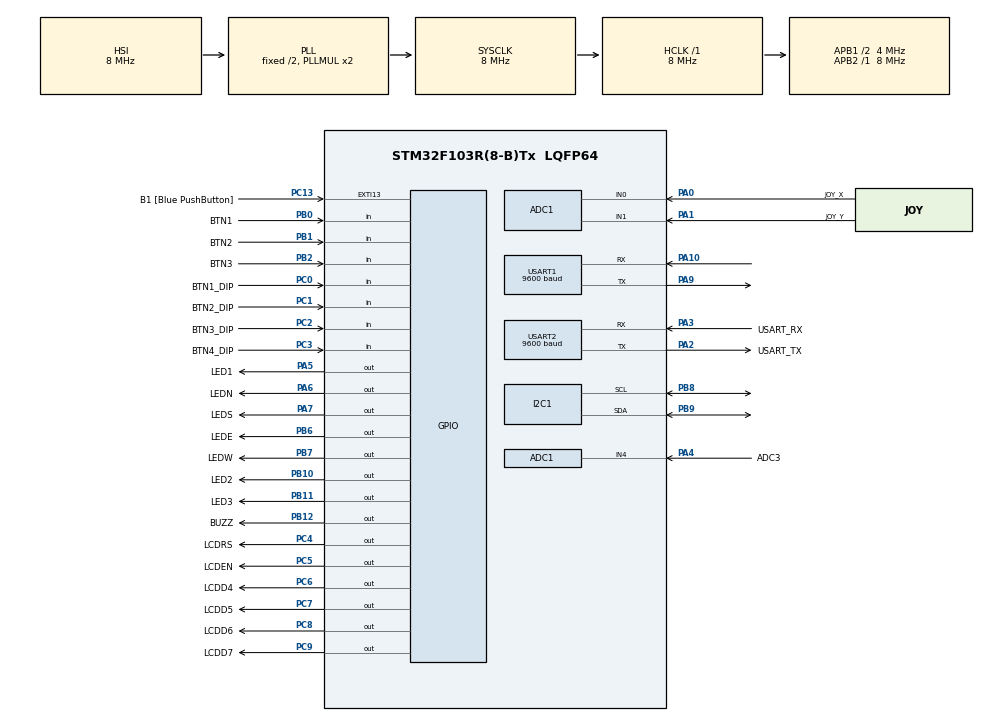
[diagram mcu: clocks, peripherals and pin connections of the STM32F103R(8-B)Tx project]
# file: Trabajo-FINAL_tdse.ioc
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ADC1.Channel-3\#ChannelRegularConversion=ADC_CHANNEL_0
ADC1.Channel-4\#ChannelRegularConversion=ADC_CHANNEL_1
ADC1.Channel-5\#ChannelRegularConversion=ADC_CHANNEL_4
ADC1.ContinuousConvMode=ENABLE
ADC1.DataAlign=ADC_DATAALIGN_RIGHT
ADC1.NbrOfConversion=3
ADC1.NbrOfConversionFlag=1
ADC1.Rank-3\#ChannelRegularConversion=1
ADC1.Rank-4\#ChannelRegularConversion=2
ADC1.Rank-5\#ChannelRegularConversion=3
ADC1.SamplingTime-3\#ChannelRegularConversion=ADC_SAMPLETIME_71CYCLES_5
ADC1.SamplingTime-4\#ChannelRegularConversion=ADC_SAMPLETIME_71CYCLES_5
ADC1.SamplingTime-5\#ChannelRegularConversion=ADC_SAMPLETIME_71CYCLES_5
ADC1.master=1
Dma.ADC1.0.Direction=DMA_PERIPH_TO_MEMORY
Dma.ADC1.0.Instance=DMA1_Channel1
Dma.ADC1.0.MemDataAlignment=DMA_MDATAALIGN_HALFWORD
Dma.ADC1.0.MemInc=DMA_MINC_ENABLE
Dma.ADC1.0.Mode=DMA_CIRCULAR
Dma.ADC1.0.PeriphDataAlignment=DMA_PDATAALIGN_HALFWORD
Dma.ADC1.0.PeriphInc=DMA_PINC_DISABLE
Dma.ADC1.0.Priority=DMA_PRIORITY_LOW
Dma.Request0=ADC1
Mcu.Family=STM32F1
Mcu.Name=STM32F103R(8-B)Tx
Mcu.Package=LQFP64
NVIC.EXTI15_10_IRQn=true\:0\:0\:false\:false\:true\:true\:true\:true
NVIC.PriorityGroup=NVIC_PRIORITYGROUP_4
NVIC.USART1_IRQn=true\:0\:0\:false\:false\:true\:true\:true\:true
NVIC.USART2_IRQn=true\:0\:0\:false\:false\:true\:true\:true\:true
PA0-WKUP.GPIO_Label=JOY_X
PA0-WKUP.Signal=ADCx_IN0
PA1.GPIO_Label=JOY_Y
PA1.Signal=ADCx_IN1
PA10.Mode=Asynchronous
PA10.Signal=USART1_RX
PA13.GPIO_Label=TMS
PA13.Mode=Serial_Wire
PA13.Signal=SYS_JTMS-SWDIO
PA14.GPIO_Label=TCK
PA14.Mode=Serial_Wire
PA14.Signal=SYS_JTCK-SWCLK
PA2.GPIO_Label=USART_TX
PA2.GPIO_Mode=GPIO_MODE_AF_PP
PA2.GPIO_PuPd=GPIO_NOPULL
PA2.GPIO_Speed=GPIO_SPEED_FREQ_LOW
PA2.Mode=Asynchronous
PA2.Signal=USART2_TX
PA3.GPIO_Label=USART_RX
PA3.GPIO_Mode=GPIO_MODE_AF_PP
PA3.GPIO_PuPd=GPIO_NOPULL
PA3.GPIO_Speed=GPIO_SPEED_FREQ_LOW
PA3.Mode=Asynchronous
PA3.Signal=USART2_RX
PA4.GPIO_Label=ADC3
PA4.Signal=ADCx_IN4
PA5.GPIO_Label=LED1
PA5.PinState=GPIO_PIN_SET
PA5.Signal=GPIO_Output
PA6.GPIO_Label=LEDN
PA6.PinState=GPIO_PIN_SET
PA6.Signal=GPIO_Output
PA7.GPIO_Label=LEDS
PA7.PinState=GPIO_PIN_SET
PA7.Signal=GPIO_Output
PA9.Mode=Asynchronous
PA9.Signal=USART1_TX
PB0.GPIO_Label=BTN1
PB0.GPIO_PuPd=GPIO_PULLUP
PB0.Signal=GPIO_Input
PB1.GPIO_Label=BTN2
PB1.GPIO_PuPd=GPIO_PULLUP
PB1.Signal=GPIO_Input
PB10.GPIO_Label=LED2
PB10.PinState=GPIO_PIN_SET
PB10.Signal=GPIO_Output
PB11.GPIO_Label=LED3
PB11.PinState=GPIO_PIN_SET
PB11.Signal=GPIO_Output
PB12.GPIO_Label=BUZZ
PB12.PinState=GPIO_PIN_SET
PB12.Signal=GPIO_Output
PB2.GPIO_Label=BTN3
PB2.GPIO_PuPd=GPIO_PULLUP
PB2.Signal=GPIO_Input
PB3.GPIO_Label=SWO
PB3.Signal=SYS_JTDO-TRACESWO
PB6.GPIO_Label=LEDE
PB6.PinState=GPIO_PIN_SET
PB6.Signal=GPIO_Output
PB7.GPIO_Label=LEDW
PB7.PinState=GPIO_PIN_SET
PB7.Signal=GPIO_Output
PB8.Mode=I2C
PB8.Signal=I2C1_SCL
PB9.Mode=I2C
PB9.Signal=I2C1_SDA
PC0.GPIO_Label=BTN1_DIP
PC0.GPIO_PuPd=GPIO_PULLUP
PC0.Signal=GPIO_Input
PC1.GPIO_Label=BTN2_DIP
PC1.GPIO_PuPd=GPIO_PULLUP
PC1.Signal=GPIO_Input
PC13-TAMPER-RTC.GPIO_Label=B1 [Blue PushButton]
PC13-TAMPER-RTC.GPIO_PuPd=GPIO_NOPULL
PC13-TAMPER-RTC.Signal=GPXTI13
PC14-OSC32_IN.Mode=LSE-External-Oscillator
PC14-OSC32_IN.Signal=RCC_OSC32_IN
PC15-OSC32_OUT.Mode=LSE-External-Oscillator
PC15-OSC32_OUT.Signal=RCC_OSC32_OUT
PC2.GPIO_Label=BTN3_DIP
PC2.GPIO_PuPd=GPIO_PULLUP
PC2.Signal=GPIO_Input
PC3.GPIO_Label=BTN4_DIP
PC3.GPIO_PuPd=GPIO_PULLUP
PC3.Signal=GPIO_Input
PC4.GPIO_Label=LCDRS
PC4.Signal=GPIO_Output
PC5.GPIO_Label=LCDEN
PC5.Signal=GPIO_Output
PC6.GPIO_Label=LCDD4
PC6.Signal=GPIO_Output
PC7.GPIO_Label=LCDD5
PC7.Signal=GPIO_Output
PC8.GPIO_Label=LCDD6
PC8.Signal=GPIO_Output
PC9.GPIO_Label=LCDD7
PC9.Signal=GPIO_Output
PD0-OSC_IN.Mode=HSE-External-Clock-Source
PD0-OSC_IN.Signal=RCC_OSC_IN
PD1-OSC_OUT.Mode=HSE-External-Clock-Source
PD1-OSC_OUT.Signal=RCC_OSC_OUT
ProjectManager.HeapSize=0x200
ProjectManager.StackSize=0x400
ProjectManager.TargetToolchain=STM32CubeIDE
RCC.AHBFreq_Value=8000000
RCC.APB1CLKDivider=RCC_HCLK_DIV2
RCC.APB1Freq_Value=4000000
RCC.APB1TimFreq_Value=8000000
RCC.APB2Freq_Value=8000000
RCC.APB2TimFreq_Value=8000000
RCC.HCLKFreq_Value=8000000
RCC.RTCClockSelection=RCC_RTCCLKSOURCE_LSE
RCC.SYSCLKFreq_VALUE=8000000
RCC.SYSCLKSource=RCC_SYSCLKSOURCE_PLLCLK
RCC.USBFreq_Value=8000000
SH.ADCx_IN0.0=ADC1_IN0,IN0
SH.ADCx_IN1.0=ADC1_IN1,IN1
SH.ADCx_IN4.0=ADC1_IN4,IN4
USART1.BaudRate=9600
USART1.VirtualMode=VM_ASYNC
USART2.BaudRate=9600
USART2.VirtualMode=VM_ASYNC
board=NUCLEO-F103RB

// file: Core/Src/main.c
/* USER CODE BEGIN Header */
/**
  ******************************************************************************
  * @file           : main.c
  * @brief          : Main program body
  ******************************************************************************
  * @attention
  *
  * Copyright (c) 2026 STMicroelectronics.
  * All rights reserved.
  *
  * This software is licensed under terms that can be found in the LICENSE file
  * in the root directory of this software component.
  * If no LICENSE file comes with this software, it is provided AS-IS.
  *
  ******************************************************************************
  */
/* USER CODE END Header */
#include "main.h"

/* USER CODE BEGIN Includes */
#include "app.h"
/* USER CODE END Includes */

ADC_HandleTypeDef hadc1;
DMA_HandleTypeDef hdma_adc1;

I2C_HandleTypeDef hi2c1;

UART_HandleTypeDef huart1;
UART_HandleTypeDef huart2;

void SystemClock_Config(void);
static void MX_GPIO_Init(void);
static void MX_DMA_Init(void);
static void MX_USART2_UART_Init(void);
static void MX_ADC1_Init(void);
static void MX_I2C1_Init(void);
static void MX_USART1_UART_Init(void);

int main(void)
{

  /* MCU Configuration--------------------------------------------------------*/

  /* Reset of all peripherals, Initializes the Flash interface and the Systick. */
  HAL_Init();

  /* Configure the system clock */
  SystemClock_Config();

  /* Initialize all configured peripherals */
  MX_GPIO_Init();
  MX_DMA_Init();
  MX_USART2_UART_Init();
  MX_ADC1_Init();
  MX_I2C1_Init();
  MX_USART1_UART_Init();
  /* USER CODE BEGIN 2 */
  app_init();
  /* USER CODE END 2 */

  /* Infinite loop */
  while (1)
  {

    /* USER CODE BEGIN 3 */
    app_update();
  }
  /* USER CODE END 3 */
}

void SystemClock_Config(void)
{
  RCC_OscInitTypeDef RCC_OscInitStruct = {0};
  RCC_ClkInitTypeDef RCC_ClkInitStruct = {0};
  RCC_PeriphCLKInitTypeDef PeriphClkInit = {0};

  /** Initializes the RCC Oscillators according to the specified parameters
  * in the RCC_OscInitTypeDef structure.
  */
  RCC_OscInitStruct.OscillatorType = RCC_OSCILLATORTYPE_HSI;
  RCC_OscInitStruct.HSIState = RCC_HSI_ON;
  RCC_OscInitStruct.HSICalibrationValue = RCC_HSICALIBRATION_DEFAULT;
  RCC_OscInitStruct.PLL.PLLState = RCC_PLL_ON;
  RCC_OscInitStruct.PLL.PLLSource = RCC_PLLSOURCE_HSI_DIV2;
  RCC_OscInitStruct.PLL.PLLMUL = RCC_PLL_MUL2;
  if (HAL_RCC_OscConfig(&RCC_OscInitStruct) != HAL_OK)
  {
    Error_Handler();
  }

  /** Initializes the CPU, AHB and APB buses clocks
  */
  RCC_ClkInitStruct.ClockType = RCC_CLOCKTYPE_HCLK|RCC_CLOCKTYPE_SYSCLK
                              |RCC_CLOCKTYPE_PCLK1|RCC_CLOCKTYPE_PCLK2;
  RCC_ClkInitStruct.SYSCLKSource = RCC_SYSCLKSOURCE_PLLCLK;
  RCC_ClkInitStruct.AHBCLKDivider = RCC_SYSCLK_DIV1;
  RCC_ClkInitStruct.APB1CLKDivider = RCC_HCLK_DIV2;
  RCC_ClkInitStruct.APB2CLKDivider = RCC_HCLK_DIV1;

  if (HAL_RCC_ClockConfig(&RCC_ClkInitStruct, FLASH_LATENCY_0) != HAL_OK)
  {
    Error_Handler();
  }
  PeriphClkInit.PeriphClockSelection = RCC_PERIPHCLK_ADC;
  PeriphClkInit.AdcClockSelection = RCC_ADCPCLK2_DIV2;
  if (HAL_RCCEx_PeriphCLKConfig(&PeriphClkInit) != HAL_OK)
  {
    Error_Handler();
  }
}

static void MX_ADC1_Init(void)
{

  ADC_ChannelConfTypeDef sConfig = {0};

  /** Common config
  */
  hadc1.Instance = ADC1;
  hadc1.Init.ScanConvMode = ADC_SCAN_ENABLE;
  hadc1.Init.ContinuousConvMode = ENABLE;
  hadc1.Init.DiscontinuousConvMode = DISABLE;
  hadc1.Init.ExternalTrigConv = ADC_SOFTWARE_START;
  hadc1.Init.DataAlign = ADC_DATAALIGN_RIGHT;
  hadc1.Init.NbrOfConversion = 3;
  if (HAL_ADC_Init(&hadc1) != HAL_OK)
  {
    Error_Handler();
  }

  /** Configure Regular Channel
  */
  sConfig.Channel = ADC_CHANNEL_0;
  sConfig.Rank = ADC_REGULAR_RANK_1;
  sConfig.SamplingTime = ADC_SAMPLETIME_71CYCLES_5;
  if (HAL_ADC_ConfigChannel(&hadc1, &sConfig) != HAL_OK)
  {
    Error_Handler();
  }

  /** Configure Regular Channel
  */
  sConfig.Channel = ADC_CHANNEL_1;
  sConfig.Rank = ADC_REGULAR_RANK_2;
  if (HAL_ADC_ConfigChannel(&hadc1, &sConfig) != HAL_OK)
  {
    Error_Handler();
  }

  /** Configure Regular Channel
  */
  sConfig.Channel = ADC_CHANNEL_4;
  sConfig.Rank = ADC_REGULAR_RANK_3;
  if (HAL_ADC_ConfigChannel(&hadc1, &sConfig) != HAL_OK)
  {
    Error_Handler();
  }

}

static void MX_I2C1_Init(void)
{

  hi2c1.Instance = I2C1;
  hi2c1.Init.ClockSpeed = 100000;
  hi2c1.Init.DutyCycle = I2C_DUTYCYCLE_2;
  hi2c1.Init.OwnAddress1 = 0;
  hi2c1.Init.AddressingMode = I2C_ADDRESSINGMODE_7BIT;
  hi2c1.Init.DualAddressMode = I2C_DUALADDRESS_DISABLE;
  hi2c1.Init.OwnAddress2 = 0;
  hi2c1.Init.GeneralCallMode = I2C_GENERALCALL_DISABLE;
  hi2c1.Init.NoStretchMode = I2C_NOSTRETCH_DISABLE;
  if (HAL_I2C_Init(&hi2c1) != HAL_OK)
  {
    Error_Handler();
  }

}

static void MX_USART1_UART_Init(void)
{

  huart1.Instance = USART1;
  huart1.Init.BaudRate = 9600;
  huart1.Init.WordLength = UART_WORDLENGTH_8B;
  huart1.Init.StopBits = UART_STOPBITS_1;
  huart1.Init.Parity = UART_PARITY_NONE;
  huart1.Init.Mode = UART_MODE_TX_RX;
  huart1.Init.HwFlowCtl = UART_HWCONTROL_NONE;
  huart1.Init.OverSampling = UART_OVERSAMPLING_16;
  if (HAL_UART_Init(&huart1) != HAL_OK)
  {
    Error_Handler();
  }

}

static void MX_USART2_UART_Init(void)
{

  huart2.Instance = USART2;
  huart2.Init.BaudRate = 9600;
  huart2.Init.WordLength = UART_WORDLENGTH_8B;
  huart2.Init.StopBits = UART_STOPBITS_1;
  huart2.Init.Parity = UART_PARITY_NONE;
  huart2.Init.Mode = UART_MODE_TX_RX;
  huart2.Init.HwFlowCtl = UART_HWCONTROL_NONE;
  huart2.Init.OverSampling = UART_OVERSAMPLING_16;
  if (HAL_UART_Init(&huart2) != HAL_OK)
  {
    Error_Handler();
  }

}

static void MX_DMA_Init(void)
{

  /* DMA controller clock enable */
  __HAL_RCC_DMA1_CLK_ENABLE();

}

static void MX_GPIO_Init(void)
{
  GPIO_InitTypeDef GPIO_InitStruct = {0};

  /* GPIO Ports Clock Enable */
  __HAL_RCC_GPIOC_CLK_ENABLE();
  __HAL_RCC_GPIOD_CLK_ENABLE();
  __HAL_RCC_GPIOA_CLK_ENABLE();
  __HAL_RCC_GPIOB_CLK_ENABLE();

  /*Configure GPIO pin Output Level */
  HAL_GPIO_WritePin(GPIOA, LED1_Pin|LEDN_Pin|LEDS_Pin, GPIO_PIN_SET);

  /*Configure GPIO pin Output Level */
  HAL_GPIO_WritePin(GPIOC, LCDRS_Pin|LCDEN_Pin|LCDD4_Pin|LCDD5_Pin
                          |LCDD6_Pin|LCDD7_Pin, GPIO_PIN_RESET);

  /*Configure GPIO pin Output Level */
  HAL_GPIO_WritePin(GPIOB, LED2_Pin|LED3_Pin|BUZZ_Pin|LEDE_Pin
                          |LEDW_Pin, GPIO_PIN_SET);

  /*Configure GPIO pin : B1_Pin */
  GPIO_InitStruct.Pin = B1_Pin;
  GPIO_InitStruct.Mode = GPIO_MODE_IT_RISING;
  GPIO_InitStruct.Pull = GPIO_NOPULL;
  HAL_GPIO_Init(B1_GPIO_Port, &GPIO_InitStruct);

  /*Configure GPIO pins : BTN1_DIP_Pin BTN2_DIP_Pin BTN3_DIP_Pin BTN4_DIP_Pin */
  GPIO_InitStruct.Pin = BTN1_DIP_Pin|BTN2_DIP_Pin|BTN3_DIP_Pin|BTN4_DIP_Pin;
  GPIO_InitStruct.Mode = GPIO_MODE_INPUT;
  GPIO_InitStruct.Pull = GPIO_PULLUP;
  HAL_GPIO_Init(GPIOC, &GPIO_InitStruct);

  /*Configure GPIO pins : LED1_Pin LEDN_Pin LEDS_Pin */
  GPIO_InitStruct.Pin = LED1_Pin|LEDN_Pin|LEDS_Pin;
  GPIO_InitStruct.Mode = GPIO_MODE_OUTPUT_PP;
  GPIO_InitStruct.Pull = GPIO_NOPULL;
  GPIO_InitStruct.Speed = GPIO_SPEED_FREQ_LOW;
  HAL_GPIO_Init(GPIOA, &GPIO_InitStruct);

  /*Configure GPIO pins : LCDRS_Pin LCDEN_Pin LCDD4_Pin LCDD5_Pin
                           LCDD6_Pin LCDD7_Pin */
  GPIO_InitStruct.Pin = LCDRS_Pin|LCDEN_Pin|LCDD4_Pin|LCDD5_Pin
                          |LCDD6_Pin|LCDD7_Pin;
  GPIO_InitStruct.Mode = GPIO_MODE_OUTPUT_PP;
  GPIO_InitStruct.Pull = GPIO_NOPULL;
  GPIO_InitStruct.Speed = GPIO_SPEED_FREQ_LOW;
  HAL_GPIO_Init(GPIOC, &GPIO_InitStruct);

  /*Configure GPIO pins : BTN1_Pin BTN2_Pin BTN3_Pin */
  GPIO_InitStruct.Pin = BTN1_Pin|BTN2_Pin|BTN3_Pin;
  GPIO_InitStruct.Mode = GPIO_MODE_INPUT;
  GPIO_InitStruct.Pull = GPIO_PULLUP;
  HAL_GPIO_Init(GPIOB, &GPIO_InitStruct);

  /*Configure GPIO pins : LED2_Pin LED3_Pin BUZZ_Pin LEDE_Pin
                           LEDW_Pin */
  GPIO_InitStruct.Pin = LED2_Pin|LED3_Pin|BUZZ_Pin|LEDE_Pin
                          |LEDW_Pin;
  GPIO_InitStruct.Mode = GPIO_MODE_OUTPUT_PP;
  GPIO_InitStruct.Pull = GPIO_NOPULL;
  GPIO_InitStruct.Speed = GPIO_SPEED_FREQ_LOW;
  HAL_GPIO_Init(GPIOB, &GPIO_InitStruct);

  /* EXTI interrupt init*/
  HAL_NVIC_SetPriority(EXTI15_10_IRQn, 0, 0);
  HAL_NVIC_EnableIRQ(EXTI15_10_IRQn);

}

void Error_Handler(void)
{
  __disable_irq();
  while (1)
  {
  }
}
